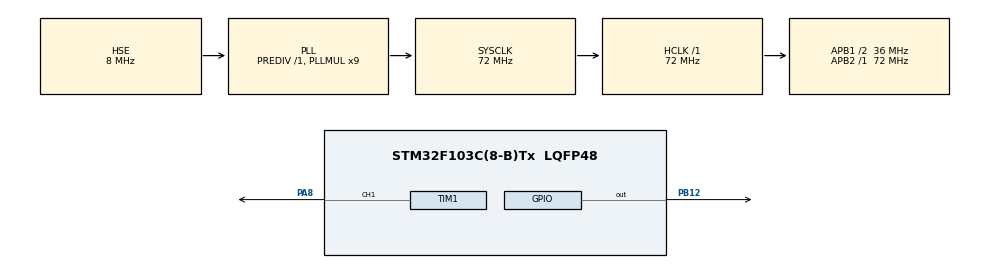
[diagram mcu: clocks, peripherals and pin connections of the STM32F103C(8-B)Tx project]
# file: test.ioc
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Mcu.Family=STM32F1
Mcu.Name=STM32F103C(8-B)Tx
Mcu.Package=LQFP48
NVIC.PriorityGroup=NVIC_PRIORITYGROUP_4
PA8.Signal=S_TIM1_CH1
PB12.PinState=GPIO_PIN_SET
PB12.Signal=GPIO_Output
PD0-OSC_IN.Mode=HSE-External-Oscillator
PD0-OSC_IN.Signal=RCC_OSC_IN
PD1-OSC_OUT.Mode=HSE-External-Oscillator
PD1-OSC_OUT.Signal=RCC_OSC_OUT
ProjectManager.HeapSize=0x200
ProjectManager.StackSize=0x400
ProjectManager.TargetToolchain=MDK-ARM V5
RCC.AHBFreq_Value=72000000
RCC.APB1CLKDivider=RCC_HCLK_DIV2
RCC.APB1Freq_Value=36000000
RCC.APB1TimFreq_Value=72000000
RCC.APB2Freq_Value=72000000
RCC.APB2TimFreq_Value=72000000
RCC.HCLKFreq_Value=72000000
RCC.PLLMUL=RCC_PLL_MUL9
RCC.PLLSourceVirtual=RCC_PLLSOURCE_HSE
RCC.SYSCLKFreq_VALUE=72000000
RCC.SYSCLKSource=RCC_SYSCLKSOURCE_PLLCLK
RCC.USBFreq_Value=72000000
SH.S_TIM1_CH1.0=TIM1_CH1,PWM Generation1 CH1
TIM1.Channel-PWM\ Generation1\ CH1=TIM_CHANNEL_1
TIM1.Period=20000
TIM1.Prescaler=72-1
VP_SYS_VS_ND.Mode=No_Debug
board=custom

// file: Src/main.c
/* USER CODE BEGIN Header */
/**
  ******************************************************************************
  * @file           : main.c
  * @brief          : Main program body
  ******************************************************************************
  * @attention
  *
  * <h2><center>&copy; Copyright (c) 2021 STMicroelectronics.
  * All rights reserved.</center></h2>
  *
  * This software component is licensed by ST under BSD 3-Clause license,
  * the "License"; You may not use this file except in compliance with the
  * License. You may obtain a copy of the License at:
  *                        opensource.org/licenses/BSD-3-Clause
  *
  ******************************************************************************
  */
/* USER CODE END Header */

#include "main.h"
#include "tim.h"
#include "gpio.h"

void SystemClock_Config(void);

/* USER CODE BEGIN 0 */
int angle,max,mix,ms;

void servo_left_light(int max, int mix, int ms);
void breathe_led();
/* USER CODE END 0 */

int main(void)
{

  /* MCU Configuration--------------------------------------------------------*/

  /* Reset of all peripherals, Initializes the Flash interface and the Systick. */
  HAL_Init();

  /* Configure the system clock */
  SystemClock_Config();

  /* Initialize all configured peripherals */
  MX_GPIO_Init();
  MX_TIM1_Init();
  /* USER CODE BEGIN 2 */
	HAL_TIM_PWM_Start(&htim1, TIM_CHANNEL_1);
  /* USER CODE END 2 */

  /* Infinite loop */
  while (1)
  {
    servo_left_light(2500, 500, 1);

  }
}

void SystemClock_Config(void)
{
  RCC_OscInitTypeDef RCC_OscInitStruct = {0};
  RCC_ClkInitTypeDef RCC_ClkInitStruct = {0};

  /** Initializes the CPU, AHB and APB busses clocks
  */
  RCC_OscInitStruct.OscillatorType = RCC_OSCILLATORTYPE_HSE;
  RCC_OscInitStruct.HSEState = RCC_HSE_ON;
  RCC_OscInitStruct.HSEPredivValue = RCC_HSE_PREDIV_DIV1;
  RCC_OscInitStruct.HSIState = RCC_HSI_ON;
  RCC_OscInitStruct.PLL.PLLState = RCC_PLL_ON;
  RCC_OscInitStruct.PLL.PLLSource = RCC_PLLSOURCE_HSE;
  RCC_OscInitStruct.PLL.PLLMUL = RCC_PLL_MUL9;
  if (HAL_RCC_OscConfig(&RCC_OscInitStruct) != HAL_OK)
  {
    Error_Handler();
  }
  /** Initializes the CPU, AHB and APB busses clocks
  */
  RCC_ClkInitStruct.ClockType = RCC_CLOCKTYPE_HCLK|RCC_CLOCKTYPE_SYSCLK
                              |RCC_CLOCKTYPE_PCLK1|RCC_CLOCKTYPE_PCLK2;
  RCC_ClkInitStruct.SYSCLKSource = RCC_SYSCLKSOURCE_PLLCLK;
  RCC_ClkInitStruct.AHBCLKDivider = RCC_SYSCLK_DIV1;
  RCC_ClkInitStruct.APB1CLKDivider = RCC_HCLK_DIV2;
  RCC_ClkInitStruct.APB2CLKDivider = RCC_HCLK_DIV1;

  if (HAL_RCC_ClockConfig(&RCC_ClkInitStruct, FLASH_LATENCY_2) != HAL_OK)
  {
    Error_Handler();
  }
}

void Error_Handler(void)
{
}

void servo_left_light(int max, int mix, int ms)
{
  for (angle = mix; angle < max; angle++)
    {
        __HAL_TIM_SET_COMPARE(&htim1, TIM_CHANNEL_1, angle);
        HAL_Delay(ms);
    }
    for (angle = max; angle >= mix; angle--)
    {
        __HAL_TIM_SET_COMPARE(&htim1, TIM_CHANNEL_1, angle);
        HAL_Delay(ms);
    }
}
void breathe_led()
{
  for (int i = 0; i < 100; i++)
  {
    HAL_Delay(i);
    HAL_GPIO_WritePin(GPIOB, GPIO_PIN_12, RESET);
    HAL_Delay(100-i);
    HAL_GPIO_WritePin(GPIOB, GPIO_PIN_12, SET);
  }
  for (int i = 100; i >= 0; i--)
  {
    HAL_Delay(i);
    HAL_GPIO_WritePin(GPIOB, GPIO_PIN_12, RESET);
    HAL_Delay(100-i);
    HAL_GPIO_WritePin(GPIOB, GPIO_PIN_12, SET);
  }
}

/************************ (C) COPYRIGHT STMicroelectronics *****END OF FILE****/
